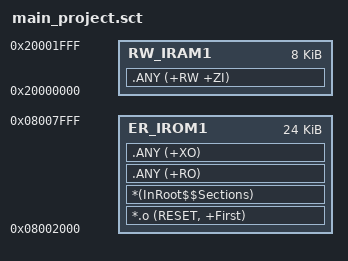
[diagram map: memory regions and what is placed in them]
; *************************************************************
; *** Scatter-Loading Description File generated by uVision ***
; *************************************************************

LR_IROM1 0x08002000 0x00006000  {   ; 24 KB for application
    ER_IROM1 0x08002000 0x00006000  {
        *.o (RESET, +First)          ; Reset vector MUST be first
        *(InRoot$$Sections)
        .ANY (+RO)                   ; Code + const
        .ANY (+XO)                   ; Exec-only sections
    }

    RW_IRAM1 0x20000000 0x00002000  { ; 8 KB SRAM
        .ANY (+RW +ZI)               ; Data + BSS
    }
}

